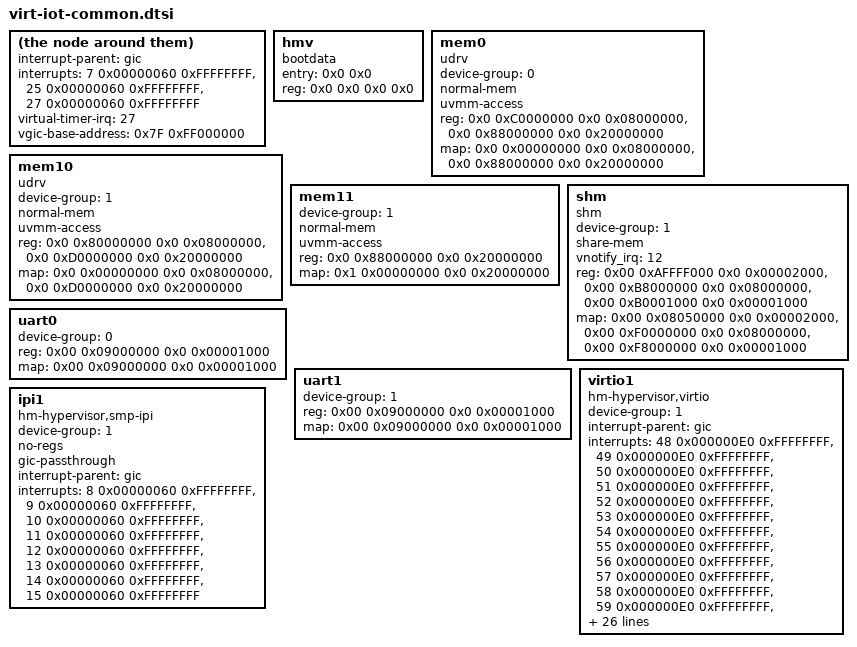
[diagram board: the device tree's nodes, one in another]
interrupt-parent = <&gic>;
interrupts =	< 7 0x00000060 0xFFFFFFFF>,
		<25 0x00000060 0xFFFFFFFF>,
		<27 0x00000060 0xFFFFFFFF>;

virtual-timer-irq = <27>;
vgic-base-address = <0x7F 0xFF000000>;

hmv {
	compatible = "bootdata";
	/* filled by bootloader */
	entry = <0x0 0x0>;
	reg = <0x0 0x0 0x0 0x0>;
};

/* Mem for device-group 0 which is based on vgic */
mem0 {
	device-group = <0>;
	compatible = "udrv";
	normal-mem;
	uvmm-access;
	reg = <0x0 0xC0000000 0x0 0x08000000>,
	      <0x0 0x88000000 0x0 0x20000000>;
	map = <0x0 0x00000000 0x0 0x08000000>,
	      <0x0 0x88000000 0x0 0x20000000>;
};

/* Mem for device-group 1 which is based on gic-passthrough */
mem10 {
	device-group = <1>;
	compatible = "udrv";
	normal-mem;
	uvmm-access;
	reg = <0x0 0x80000000 0x0 0x08000000>,
	      <0x0 0xD0000000 0x0 0x20000000>;
	map = <0x0 0x00000000 0x0 0x08000000>,
	      <0x0 0xD0000000 0x0 0x20000000>;
};

/* Map device-group<0> memory to device-group<1> */
mem11 {
	device-group = <1>;
	normal-mem;
	uvmm-access;
	reg = <0x0 0x88000000 0x0 0x20000000>;
	map = <0x1 0x00000000 0x0 0x20000000>;
};

shm {
	device-group = <1>;
	compatible = "shm","udrv";
	share-mem;
	vnotify_irq = <12>;
	/*
	 * GPA address, length and the segments order
	 * are consistent with hpe. Modify them carefully!
	 */
	reg = <0x00 0xAFFFF000 0x0 0x00002000>,
	      <0x00 0xB8000000 0x0 0x08000000>,
	      <0x00 0xB0001000 0x0 0x00001000>;
	map = <0x00 0x08050000 0x0 0x00002000>,
	      <0x00 0xF0000000 0x0 0x08000000>,
	      <0x00 0xF8000000 0x0 0x00001000>;
};

uart0 {
	device-group = <0>;
	reg = <0x00 0x09000000 0x0 0x00001000>;
	map = <0x00 0x09000000 0x0 0x00001000>;
};

uart1 {
	device-group = <1>;
	reg = <0x00 0x09000000 0x0 0x00001000>;
	map = <0x00 0x09000000 0x0 0x00001000>;
};

/*
 * Each interrupt can only be registered to one vm now, host should not
 * receive IRQs from a vm based on vgic, so we just register the IRQs
 * for a vm based on gic-passthrough.
 */
virtio1 {
	device-group = <1>;
	compatible = "hm-hypervisor,virtio";
	interrupt-parent = <&gic>;
	interrupts =	<48 0x000000E0 0xFFFFFFFF>,
			<49 0x000000E0 0xFFFFFFFF>,
			<50 0x000000E0 0xFFFFFFFF>,
			<51 0x000000E0 0xFFFFFFFF>,
			<52 0x000000E0 0xFFFFFFFF>,
			<53 0x000000E0 0xFFFFFFFF>,
			<54 0x000000E0 0xFFFFFFFF>,
			<55 0x000000E0 0xFFFFFFFF>,
			<56 0x000000E0 0xFFFFFFFF>,
			<57 0x000000E0 0xFFFFFFFF>,
			<58 0x000000E0 0xFFFFFFFF>,
			<59 0x000000E0 0xFFFFFFFF>,
			<60 0x000000E0 0xFFFFFFFF>,
			<61 0x000000E0 0xFFFFFFFF>,
			<62 0x000000E0 0xFFFFFFFF>,
			<63 0x000000E0 0xFFFFFFFF>,
			<64 0x000000E0 0xFFFFFFFF>,
			<65 0x000000E0 0xFFFFFFFF>,
			<66 0x000000E0 0xFFFFFFFF>,
			<67 0x000000E0 0xFFFFFFFF>,
			<68 0x000000E0 0xFFFFFFFF>,
			<69 0x000000E0 0xFFFFFFFF>,
			<70 0x000000E0 0xFFFFFFFF>,
			<71 0x000000E0 0xFFFFFFFF>,
			<72 0x000000E0 0xFFFFFFFF>,
			<73 0x000000E0 0xFFFFFFFF>,
			<74 0x000000E0 0xFFFFFFFF>,
			<75 0x000000E0 0xFFFFFFFF>,
			<76 0x000000E0 0xFFFFFFFF>,
			<77 0x000000E0 0xFFFFFFFF>,
			<78 0x000000E0 0xFFFFFFFF>,
			<96 0x000000E0 0xFFFFFFFF>,
			<97 0x000000E0 0xFFFFFFFF>,
			<98 0x000000E0 0xFFFFFFFF>,
			<99 0x000000E0 0xFFFFFFFF>,
			<100 0x000000E0 0xFFFFFFFF>;
	reg = <0x0 0x0A000000 0x0 0x00004000>;
	map = <0x0 0x0A000000 0x0 0x00004000>;
};

ipi1 {
	device-group = <1>;
	compatible = "hm-hypervisor,smp-ipi";
	no-regs;
	gic-passthrough;
	interrupt-parent = <&gic>;
	interrupts =	< 8 0x00000060 0xFFFFFFFF>,
			< 9 0x00000060 0xFFFFFFFF>,
			<10 0x00000060 0xFFFFFFFF>,
			<11 0x00000060 0xFFFFFFFF>,
			<12 0x00000060 0xFFFFFFFF>, /* vnotify */
			<13 0x00000060 0xFFFFFFFF>,
			<14 0x00000060 0xFFFFFFFF>,
			<15 0x00000060 0xFFFFFFFF>;
};
